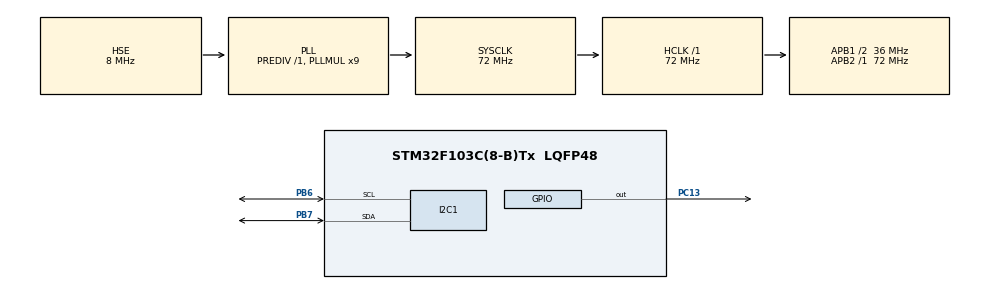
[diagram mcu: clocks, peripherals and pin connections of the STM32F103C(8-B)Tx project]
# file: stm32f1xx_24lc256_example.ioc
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I2C1.I2C_Mode=I2C_Fast
Mcu.Family=STM32F1
Mcu.Name=STM32F103C(8-B)Tx
Mcu.Package=LQFP48
NVIC.PriorityGroup=NVIC_PRIORITYGROUP_4
PA13.Mode=Serial_Wire
PA13.Signal=SYS_JTMS-SWDIO
PA14.Mode=Serial_Wire
PA14.Signal=SYS_JTCK-SWCLK
PB6.Mode=I2C
PB6.Signal=I2C1_SCL
PB7.Mode=I2C
PB7.Signal=I2C1_SDA
PC13-TAMPER-RTC.Signal=GPIO_Output
PD0-OSC_IN.Mode=HSE-External-Oscillator
PD0-OSC_IN.Signal=RCC_OSC_IN
PD1-OSC_OUT.Mode=HSE-External-Oscillator
PD1-OSC_OUT.Signal=RCC_OSC_OUT
ProjectManager.HeapSize=0x200
ProjectManager.StackSize=0x400
ProjectManager.TargetToolchain=STM32CubeIDE
RCC.AHBFreq_Value=72000000
RCC.APB1CLKDivider=RCC_HCLK_DIV2
RCC.APB1Freq_Value=36000000
RCC.APB1TimFreq_Value=72000000
RCC.APB2Freq_Value=72000000
RCC.APB2TimFreq_Value=72000000
RCC.HCLKFreq_Value=72000000
RCC.PLLMUL=RCC_PLL_MUL9
RCC.PLLSourceVirtual=RCC_PLLSOURCE_HSE
RCC.SYSCLKFreq_VALUE=72000000
RCC.SYSCLKSource=RCC_SYSCLKSOURCE_PLLCLK
RCC.USBFreq_Value=72000000
board=custom

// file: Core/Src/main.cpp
/* USER CODE BEGIN Header */
/**
 ******************************************************************************
 * @file           : main.c
 * @brief          : Main program body
 ******************************************************************************
 * @attention
 *
 * <h2><center>&copy; Copyright (c) 2020 STMicroelectronics.
 * All rights reserved.</center></h2>
 *
 * This software component is licensed by ST under BSD 3-Clause license,
 * the "License"; You may not use this file except in compliance with the
 * License. You may obtain a copy of the License at:
 *                        opensource.org/licenses/BSD-3-Clause
 *
 ******************************************************************************
 */
/* USER CODE END Header */
#include "main.h"

I2C_HandleTypeDef hi2c1;

/* USER CODE BEGIN PV */

/* funciona para memorias EEPROM 24aaXXX, 24lcXXX, 24aaXX, 24lcXX. */
typedef enum
{
    ADD_SIZE_8BIT = 0x01,
    ADD_SIZE_16BIT = 0x10,
} Address_size_t;

class Eeprom_24lcxxx
{
private:

    I2C_HandleTypeDef *i2c;
    uint8_t _DevAddress;  // direccion del esclavo i2c
    uint8_t _MemAddSize;  // tamaño del la direccion de memoria 8 o 16 bits

public:

    Eeprom_24lcxxx( I2C_HandleTypeDef * _i2c, uint8_t DevAddress,
            Address_size_t MemAddSize );
    void Read( uint16_t address, uint8_t * data, uint16_t size );
    void Write( uint16_t address, uint8_t * data, uint16_t size );

};

/**
 *
 * @param _i2c  puntero a la estructura I2C_HandleTypeDef que contiene
 *              la nformacion del i2c
 * @param DevAddress  direccion del esclavo i2c
 * @param MemAddSize  tamaño de la direccion de memoria, depende del tipo
 *                    de memoria que se utilice.
 */
Eeprom_24lcxxx::Eeprom_24lcxxx( I2C_HandleTypeDef * _i2c, uint8_t DevAddress,
        Address_size_t MemAddSize )
{
    i2c = _i2c;
    _DevAddress = DevAddress << 1;
    _MemAddSize = MemAddSize;
}

/**
 *
 * @param MemAddress direccion de memoria
 * @param data  puntero de datos recibidos
 * @param size  cantidad de datos a leer
 */
void Eeprom_24lcxxx::Read( uint16_t MemAddress, uint8_t * data, uint16_t size )
{
        HAL_I2C_Mem_Read( i2c, _DevAddress, MemAddress, _MemAddSize, data, size,
                500 );
}

/**
 *
 * @param MemAddress  direccion de memoria
 * @param data  puntero de datos para escribir
 * @param size  cantidad de datos a leer
 */
void Eeprom_24lcxxx::Write( uint16_t MemAddress, uint8_t * data, uint16_t size )
{
          HAL_I2C_Mem_Write( i2c, _DevAddress, MemAddress, _MemAddSize, data, size,
                500 );
}

/* declaracion de la clase con direccon de memoria 0x50 pines A0=A1=A2=0
 * este ejemplo se realizo con la memoria eeprom 24lc256 */
Eeprom_24lcxxx eeprom( &hi2c1, 0x50, ADD_SIZE_16BIT );

uint8_t dataWrite[] =
{ 10, 11, 12, 13, 14 };
uint8_t dataRead[5];

/* USER CODE END PV */

void SystemClock_Config(void);
static void MX_GPIO_Init(void);
static void MX_I2C1_Init(void);

int main(void)
{

  /* MCU Configuration--------------------------------------------------------*/

  /* Reset of all peripherals, Initializes the Flash interface and the Systick. */
  HAL_Init();

  /* Configure the system clock */
  SystemClock_Config();

  /* Initialize all configured peripherals */
  MX_GPIO_Init();
  MX_I2C1_Init();
  /* USER CODE BEGIN 2 */

    eeprom.Read( 0x00, dataRead, 5 );

    eeprom.Write( 0x00, dataWrite, 5 );
    HAL_Delay( 10 );   // la escritura de un byte o pagina tarda 5ms aprox.

    eeprom.Read( 0x00, dataRead, 5 );

  /* USER CODE END 2 */

  /* Infinite loop */
    while ( 1 )
    {

    }
}

void SystemClock_Config(void)
{
  RCC_OscInitTypeDef RCC_OscInitStruct = {0};
  RCC_ClkInitTypeDef RCC_ClkInitStruct = {0};

  /** Initializes the RCC Oscillators according to the specified parameters
  * in the RCC_OscInitTypeDef structure.
  */
  RCC_OscInitStruct.OscillatorType = RCC_OSCILLATORTYPE_HSE;
  RCC_OscInitStruct.HSEState = RCC_HSE_ON;
  RCC_OscInitStruct.HSEPredivValue = RCC_HSE_PREDIV_DIV1;
  RCC_OscInitStruct.HSIState = RCC_HSI_ON;
  RCC_OscInitStruct.PLL.PLLState = RCC_PLL_ON;
  RCC_OscInitStruct.PLL.PLLSource = RCC_PLLSOURCE_HSE;
  RCC_OscInitStruct.PLL.PLLMUL = RCC_PLL_MUL9;
  if (HAL_RCC_OscConfig(&RCC_OscInitStruct) != HAL_OK)
  {
    Error_Handler();
  }
  /** Initializes the CPU, AHB and APB buses clocks
  */
  RCC_ClkInitStruct.ClockType = RCC_CLOCKTYPE_HCLK|RCC_CLOCKTYPE_SYSCLK
                              |RCC_CLOCKTYPE_PCLK1|RCC_CLOCKTYPE_PCLK2;
  RCC_ClkInitStruct.SYSCLKSource = RCC_SYSCLKSOURCE_PLLCLK;
  RCC_ClkInitStruct.AHBCLKDivider = RCC_SYSCLK_DIV1;
  RCC_ClkInitStruct.APB1CLKDivider = RCC_HCLK_DIV2;
  RCC_ClkInitStruct.APB2CLKDivider = RCC_HCLK_DIV1;

  if (HAL_RCC_ClockConfig(&RCC_ClkInitStruct, FLASH_LATENCY_2) != HAL_OK)
  {
    Error_Handler();
  }
}

static void MX_I2C1_Init(void)
{

  hi2c1.Instance = I2C1;
  hi2c1.Init.ClockSpeed = 400000;
  hi2c1.Init.DutyCycle = I2C_DUTYCYCLE_2;
  hi2c1.Init.OwnAddress1 = 0;
  hi2c1.Init.AddressingMode = I2C_ADDRESSINGMODE_7BIT;
  hi2c1.Init.DualAddressMode = I2C_DUALADDRESS_DISABLE;
  hi2c1.Init.OwnAddress2 = 0;
  hi2c1.Init.GeneralCallMode = I2C_GENERALCALL_DISABLE;
  hi2c1.Init.NoStretchMode = I2C_NOSTRETCH_DISABLE;
  if (HAL_I2C_Init(&hi2c1) != HAL_OK)
  {
    Error_Handler();
  }

}

static void MX_GPIO_Init(void)
{
  GPIO_InitTypeDef GPIO_InitStruct = {0};

  /* GPIO Ports Clock Enable */
  __HAL_RCC_GPIOC_CLK_ENABLE();
  __HAL_RCC_GPIOD_CLK_ENABLE();
  __HAL_RCC_GPIOA_CLK_ENABLE();
  __HAL_RCC_GPIOB_CLK_ENABLE();

  /*Configure GPIO pin Output Level */
  HAL_GPIO_WritePin(GPIOC, GPIO_PIN_13, GPIO_PIN_RESET);

  /*Configure GPIO pin : PC13 */
  GPIO_InitStruct.Pin = GPIO_PIN_13;
  GPIO_InitStruct.Mode = GPIO_MODE_OUTPUT_PP;
  GPIO_InitStruct.Pull = GPIO_NOPULL;
  GPIO_InitStruct.Speed = GPIO_SPEED_FREQ_LOW;
  HAL_GPIO_Init(GPIOC, &GPIO_InitStruct);

}

void Error_Handler(void)
{
    __disable_irq();
    while ( 1 )
    {
    }
}

/************************ (C) COPYRIGHT STMicroelectronics *****END OF FILE****/
